# PMAP_356.0 register map
Vendor: Texas Instruments
Peripheral module from a debugger description file (folder MSP432).
Registers are 16-bit, access not given, no defined reset value unless marked. A register's access mark holds for its fields unless they carry their own. Offsets are as the file gives them; lines under a group give offsets from that group; [hi:lo] are bit positions; {n}, {i} and the like mark numbered series; 'fields as' and 'values as' point back to an identical list; <NAME> marks a mode.

## PMAP
0x00 PMAPKEYID — Port Mapping Key Register
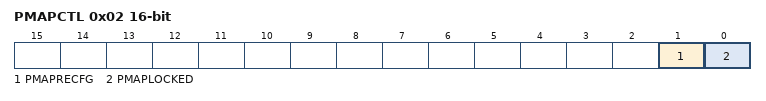
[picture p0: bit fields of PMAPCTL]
0x02 PMAPCTL access per field — Port Mapping Control Register
  [1] PMAPRECFG rw — Port mapping reconfiguration control bit
    0=Configuration allowed only once; 1=Allow reconfiguration of port mapping
  [0] PMAPLOCKED ro — Port mapping lock bit
    0=Access to mapping registers is granted; 1=Access to mapping registers is locked
0x08 P1MAP01 — Port mapping register, P1.0 and P1.1
0x0A P1MAP23 — Port mapping register, P1.2 and P1.3
0x0C P1MAP45 — Port mapping register, P1.4 and P1.5
0x0E P1MAP67 — Port mapping register, P1.6 and P1.7
0x10 P2MAP01 — Port mapping register, P2.0 and P2.1
0x12 P2MAP23 — Port mapping register, P2.2 and P2.3
0x14 P2MAP45 — Port mapping register, P2.4 and P2.5
0x16 P2MAP67 — Port mapping register, P2.6 and P2.7
0x18 P3MAP01 — Port mapping register, P3.0 and P3.1
0x1A P3MAP23 — Port mapping register, P3.2 and P3.3
0x1C P3MAP45 — Port mapping register, P3.4 and P3.5
0x1E P3MAP67 — Port mapping register, P3.6 and P3.7
0x20 P4MAP01 — Port mapping register, P4.0 and P4.1
0x22 P4MAP23 — Port mapping register, P4.2 and P4.3
0x24 P4MAP45 — Port mapping register, P4.4 and P4.5
0x26 P4MAP67 — Port mapping register, P4.6 and P4.7
0x28 P5MAP01 — Port mapping register, P5.0 and P5.1
0x2A P5MAP23 — Port mapping register, P5.2 and P5.3
0x2C P5MAP45 — Port mapping register, P5.4 and P5.5
0x2E P5MAP67 — Port mapping register, P5.6 and P5.7
0x30 P6MAP01 — Port mapping register, P6.0 and P6.1
0x32 P6MAP23 — Port mapping register, P6.2 and P6.3
0x34 P6MAP45 — Port mapping register, P6.4 and P6.5
0x36 P6MAP67 — Port mapping register, P6.6 and P6.7
0x38 P7MAP01 — Port mapping register, P7.0 and P7.1
0x3A P7MAP23 — Port mapping register, P7.2 and P7.3
0x3C P7MAP45 — Port mapping register, P7.4 and P7.5
0x3E P7MAP67 — Port mapping register, P7.6 and P7.7
